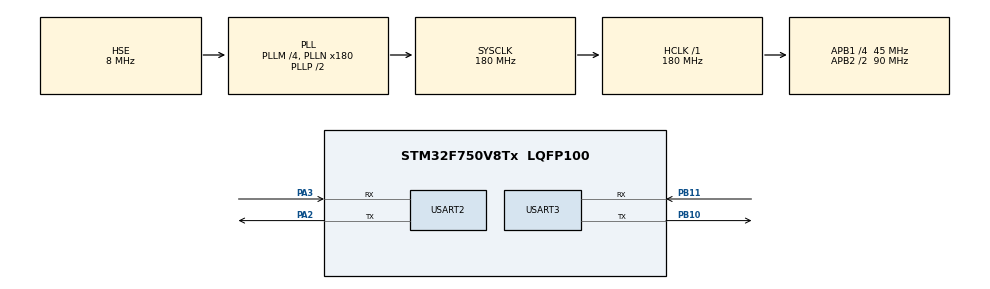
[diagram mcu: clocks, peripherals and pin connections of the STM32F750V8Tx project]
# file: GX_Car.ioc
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CORTEX_M7.CPU_DCache=Disabled
CORTEX_M7.CPU_ICache=Enabled
CORTEX_M7.Enable_Spec=__NULL
CORTEX_M7.MPU_Control=__NULL
CORTEX_M7.PREFETCH_ENABLE=1
CORTEX_M7.default_mode_Activation=1
Dma.Request0=USART3_RX
Dma.Request1=USART2_RX
Dma.USART2_RX.1.Direction=DMA_PERIPH_TO_MEMORY
Dma.USART2_RX.1.FIFOMode=DMA_FIFOMODE_DISABLE
Dma.USART2_RX.1.Instance=DMA1_Stream5
Dma.USART2_RX.1.MemDataAlignment=DMA_MDATAALIGN_BYTE
Dma.USART2_RX.1.MemInc=DMA_MINC_ENABLE
Dma.USART2_RX.1.Mode=DMA_CIRCULAR
Dma.USART2_RX.1.PeriphDataAlignment=DMA_PDATAALIGN_BYTE
Dma.USART2_RX.1.PeriphInc=DMA_PINC_DISABLE
Dma.USART2_RX.1.Priority=DMA_PRIORITY_LOW
Dma.USART3_RX.0.Direction=DMA_PERIPH_TO_MEMORY
Dma.USART3_RX.0.FIFOMode=DMA_FIFOMODE_DISABLE
Dma.USART3_RX.0.Instance=DMA1_Stream1
Dma.USART3_RX.0.MemDataAlignment=DMA_MDATAALIGN_BYTE
Dma.USART3_RX.0.MemInc=DMA_MINC_ENABLE
Dma.USART3_RX.0.Mode=DMA_NORMAL
Dma.USART3_RX.0.PeriphDataAlignment=DMA_PDATAALIGN_BYTE
Dma.USART3_RX.0.PeriphInc=DMA_PINC_DISABLE
Dma.USART3_RX.0.Priority=DMA_PRIORITY_LOW
FREERTOS.Tasks01=defaultTask,0,128,StartDefaultTask,Default,NULL,Dynamic,NULL,NULL
Mcu.Family=STM32F7
Mcu.Name=STM32F750V8Tx
Mcu.Package=LQFP100
NVIC.DMA1_Stream1_IRQn=true\:5\:0\:true\:false\:true\:true\:false\:true\:true
NVIC.DMA1_Stream5_IRQn=true\:5\:0\:false\:false\:true\:true\:false\:true\:true
NVIC.PriorityGroup=NVIC_PRIORITYGROUP_4
NVIC.TIM6_DAC_IRQn=true\:15\:0\:true\:false\:true\:true\:true\:true\:true
NVIC.TIM8_TRG_COM_TIM14_IRQn=true\:15\:0\:false\:false\:true\:false\:true\:true\:true
NVIC.TimeBase=TIM8_TRG_COM_TIM14_IRQn
NVIC.TimeBaseIP=TIM14
NVIC.USART2_IRQn=true\:2\:0\:true\:false\:true\:true\:true\:true\:true
NVIC.USART3_IRQn=true\:2\:0\:true\:false\:true\:true\:true\:true\:true
PA13.Mode=Serial_Wire
PA13.Signal=SYS_JTMS-SWDIO
PA14.Mode=Serial_Wire
PA14.Signal=SYS_JTCK-SWCLK
PA2.Mode=Asynchronous
PA2.Signal=USART2_TX
PA3.Mode=Asynchronous
PA3.Signal=USART2_RX
PB10.Mode=Asynchronous
PB10.Signal=USART3_TX
PB11.Mode=Asynchronous
PB11.Signal=USART3_RX
PH0/OSC_IN.Mode=HSE-External-Oscillator
PH0/OSC_IN.Signal=RCC_OSC_IN
PH1/OSC_OUT.Mode=HSE-External-Oscillator
PH1/OSC_OUT.Signal=RCC_OSC_OUT
ProjectManager.HeapSize=0x200
ProjectManager.StackSize=0x400
ProjectManager.TargetToolchain=CMake
RCC.AHBFreq_Value=180000000
RCC.APB1CLKDivider=RCC_HCLK_DIV4
RCC.APB1Freq_Value=45000000
RCC.APB1TimFreq_Value=90000000
RCC.APB2CLKDivider=RCC_HCLK_DIV2
RCC.APB2Freq_Value=90000000
RCC.APB2TimFreq_Value=180000000
RCC.CortexFreq_Value=180000000
RCC.HCLKFreq_Value=180000000
RCC.HSE_VALUE=8000000
RCC.HSI_VALUE=16000000
RCC.LSE_VALUE=32768
RCC.PLLM=4
RCC.PLLN=180
RCC.PLLSourceVirtual=RCC_PLLSOURCE_HSE
RCC.SYSCLKFreq_VALUE=180000000
RCC.SYSCLKSource=RCC_SYSCLKSOURCE_PLLCLK
RCC.USBFreq_Value=180000000
RCC.VCOOutputFreq_Value=360000000
TIM6.AutoReloadPreload=TIM_AUTORELOAD_PRELOAD_ENABLE
TIM6.Period=100-1
TIM6.Prescaler=900-1
USART2.VirtualMode-Asynchronous=VM_ASYNC
USART3.VirtualMode-Asynchronous=VM_ASYNC
VP_FREERTOS_VS_CMSIS_V1.Mode=CMSIS_V1
VP_SYS_VS_tim14.Mode=TIM14
VP_TIM6_VS_ClockSourceINT.Mode=Enable_Timer
board=custom

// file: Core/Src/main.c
/* USER CODE BEGIN Header */
/**
  ******************************************************************************
  * @file           : main.c
  * @brief          : Main program body
  ******************************************************************************
  * @attention
  *
  * Copyright (c) 2026 STMicroelectronics.
  * All rights reserved.
  *
  * This software is licensed under terms that can be found in the LICENSE file
  * in the root directory of this software component.
  * If no LICENSE file comes with this software, it is provided AS-IS.
  *
  ******************************************************************************
  */
/* USER CODE END Header */
#include "main.h"
#include "cmsis_os.h"
#include "dma.h"
#include "tim.h"
#include "usart.h"
#include "gpio.h"

/* USER CODE BEGIN PV */
extern uint16_t delay_time;
/* USER CODE END PV */

void SystemClock_Config(void);
void MX_FREERTOS_Init(void);

int main(void)
{

  /* Enable the CPU Cache */

  /* Enable I-Cache---------------------------------------------------------*/
  SCB_EnableICache();

  /* MCU Configuration--------------------------------------------------------*/

  /* Reset of all peripherals, Initializes the Flash interface and the Systick. */
  HAL_Init();

  /* Configure the system clock */
  SystemClock_Config();

  /* Initialize all configured peripherals */
  MX_GPIO_Init();
  MX_DMA_Init();
  MX_USART3_UART_Init();
  MX_USART2_UART_Init();
  MX_TIM6_Init();

  /* Call init function for freertos objects (in cmsis_os2.c) */
  MX_FREERTOS_Init();

  /* Start scheduler */
  osKernelStart();

  /* We should never get here as control is now taken by the scheduler */

  /* Infinite loop */
  while (1)
  {

  }
}

void SystemClock_Config(void)
{
  RCC_OscInitTypeDef RCC_OscInitStruct = {0};
  RCC_ClkInitTypeDef RCC_ClkInitStruct = {0};

  /** Configure the main internal regulator output voltage
  */
  __HAL_RCC_PWR_CLK_ENABLE();
  __HAL_PWR_VOLTAGESCALING_CONFIG(PWR_REGULATOR_VOLTAGE_SCALE1);

  /** Initializes the RCC Oscillators according to the specified parameters
  * in the RCC_OscInitTypeDef structure.
  */
  RCC_OscInitStruct.OscillatorType = RCC_OSCILLATORTYPE_HSE;
  RCC_OscInitStruct.HSEState = RCC_HSE_ON;
  RCC_OscInitStruct.PLL.PLLState = RCC_PLL_ON;
  RCC_OscInitStruct.PLL.PLLSource = RCC_PLLSOURCE_HSE;
  RCC_OscInitStruct.PLL.PLLM = 4;
  RCC_OscInitStruct.PLL.PLLN = 180;
  RCC_OscInitStruct.PLL.PLLP = RCC_PLLP_DIV2;
  RCC_OscInitStruct.PLL.PLLQ = 2;
  if (HAL_RCC_OscConfig(&RCC_OscInitStruct) != HAL_OK)
  {
    Error_Handler();
  }

  /** Initializes the CPU, AHB and APB buses clocks
  */
  RCC_ClkInitStruct.ClockType = RCC_CLOCKTYPE_HCLK|RCC_CLOCKTYPE_SYSCLK
                              |RCC_CLOCKTYPE_PCLK1|RCC_CLOCKTYPE_PCLK2;
  RCC_ClkInitStruct.SYSCLKSource = RCC_SYSCLKSOURCE_PLLCLK;
  RCC_ClkInitStruct.AHBCLKDivider = RCC_SYSCLK_DIV1;
  RCC_ClkInitStruct.APB1CLKDivider = RCC_HCLK_DIV4;
  RCC_ClkInitStruct.APB2CLKDivider = RCC_HCLK_DIV2;

  if (HAL_RCC_ClockConfig(&RCC_ClkInitStruct, FLASH_LATENCY_5) != HAL_OK)
  {
    Error_Handler();
  }
}

void HAL_TIM_PeriodElapsedCallback(TIM_HandleTypeDef *htim)
{
  if (htim->Instance == TIM14) {
    HAL_IncTick();
  }
  /* USER CODE BEGIN Callback 1 */
  if (htim->Instance == TIM6)
  {
      delay_time++;
  }
  /* USER CODE END Callback 1 */
}

void Error_Handler(void)
{
  __disable_irq();
  while (1)
  {
  }
}

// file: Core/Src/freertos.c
/* USER CODE BEGIN Header */
/**
  ******************************************************************************
  * File Name          : freertos.c
  * Description        : Code for freertos applications
  ******************************************************************************
  * @attention
  *
  * Copyright (c) 2026 STMicroelectronics.
  * All rights reserved.
  *
  * This software is licensed under terms that can be found in the LICENSE file
  * in the root directory of this software component.
  * If no LICENSE file comes with this software, it is provided AS-IS.
  *
  ******************************************************************************
  */
/* USER CODE END Header */

#include "FreeRTOS.h"
#include "task.h"
#include "main.h"
#include "cmsis_os.h"

/* USER CODE BEGIN Includes */
#include "start_task.h"
/* USER CODE END Includes */

osThreadId defaultTaskHandle;

void StartDefaultTask(void const * argument);

void MX_FREERTOS_Init(void); /* (MISRA C 2004 rule 8.1) */

/* GetIdleTaskMemory prototype (linked to static allocation support) */
void vApplicationGetIdleTaskMemory( StaticTask_t **ppxIdleTaskTCBBuffer, StackType_t **ppxIdleTaskStackBuffer, uint32_t *pulIdleTaskStackSize );

/* USER CODE BEGIN GET_IDLE_TASK_MEMORY */
static StaticTask_t xIdleTaskTCBBuffer;
static StackType_t xIdleStack[configMINIMAL_STACK_SIZE];

void vApplicationGetIdleTaskMemory( StaticTask_t **ppxIdleTaskTCBBuffer, StackType_t **ppxIdleTaskStackBuffer, uint32_t *pulIdleTaskStackSize )
{
  *ppxIdleTaskTCBBuffer = &xIdleTaskTCBBuffer;
  *ppxIdleTaskStackBuffer = &xIdleStack[0];
  *pulIdleTaskStackSize = configMINIMAL_STACK_SIZE;
  /* place for user code */
}
/* USER CODE END GET_IDLE_TASK_MEMORY */

void MX_FREERTOS_Init(void) {

  /* Create the thread(s) */
  /* definition and creation of defaultTask */
  osThreadDef(defaultTask, StartDefaultTask, osPriorityNormal, 0, 128);
  defaultTaskHandle = osThreadCreate(osThread(defaultTask), NULL);

  /* USER CODE BEGIN RTOS_THREADS */
  /* add threads, ... */
  Start_Task_Create();
  /* USER CODE END RTOS_THREADS */

}

void StartDefaultTask(void const * argument)
{
  for(;;)
  {
    osDelay(1);
  }
}
